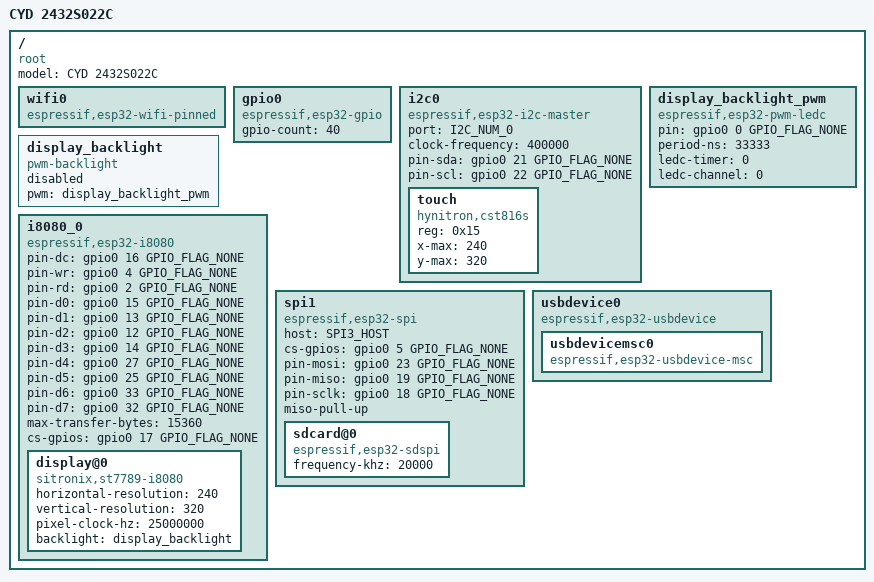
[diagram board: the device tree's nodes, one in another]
/dts-v1/;

#include <tactility/bindings/root.h>
#include <tactility/bindings/esp32_wifi_pinned.h>
#include <tactility/bindings/esp32_gpio.h>
#include <tactility/bindings/esp32_i2c_master.h>
#include <tactility/bindings/esp32_spi.h>
#include <tactility/bindings/esp32_sdspi.h>
#include <tactility/bindings/esp32_i8080.h>
#include <tactility/bindings/esp32_pwm_ledc.h>
#include <tactility/bindings/pwm_backlight.h>
#include <tactility/bindings/esp32_usbdevice.h>
#include <bindings/st7789_i8080.h>
#include <bindings/cst816s.h>

/ {
	compatible = "root";
	model = "CYD 2432S022C";

	wifi0 {
		compatible = "espressif,esp32-wifi-pinned";
	};

	gpio0 {
		compatible = "espressif,esp32-gpio";
		gpio-count = <40>;
	};

	i2c0 {
		compatible = "espressif,esp32-i2c-master";
		port = <I2C_NUM_0>;
		clock-frequency = <400000>;
		pin-sda = <&gpio0 21 GPIO_FLAG_NONE>;
		pin-scl = <&gpio0 22 GPIO_FLAG_NONE>;

		touch {
			compatible = "hynitron,cst816s";
			reg = <0x15>;
			x-max = <240>;
			y-max = <320>;
		};
	};

	display_backlight_pwm {
		compatible = "espressif,esp32-pwm-ledc";
		pin = <&gpio0 0 GPIO_FLAG_NONE>;
		period-ns = <33333>;
		ledc-timer = <0>;
		ledc-channel = <0>;
	};

	display_backlight {
		compatible = "pwm-backlight";
		// Off by default so display power-on won't show the screen from before the last power loss.
		// The display backlight is turned on during the boot process.
		status = "disabled";
		pwm = <&display_backlight_pwm>;
	};

	i8080_0 {
		compatible = "espressif,esp32-i8080";
		pin-dc = <&gpio0 16 GPIO_FLAG_NONE>;
		pin-wr = <&gpio0 4 GPIO_FLAG_NONE>;
		pin-rd = <&gpio0 2 GPIO_FLAG_NONE>;
		pin-d0 = <&gpio0 15 GPIO_FLAG_NONE>;
		pin-d1 = <&gpio0 13 GPIO_FLAG_NONE>;
		pin-d2 = <&gpio0 12 GPIO_FLAG_NONE>;
		pin-d3 = <&gpio0 14 GPIO_FLAG_NONE>;
		pin-d4 = <&gpio0 27 GPIO_FLAG_NONE>;
		pin-d5 = <&gpio0 25 GPIO_FLAG_NONE>;
		pin-d6 = <&gpio0 33 GPIO_FLAG_NONE>;
		pin-d7 = <&gpio0 32 GPIO_FLAG_NONE>;
		// 240 * (320 / 10 partial buffer) * 2 bytes/pixel = 15360 bytes
		max-transfer-bytes = <15360>;
		cs-gpios = <&gpio0 17 GPIO_FLAG_NONE>;

		display@0 {
			compatible = "sitronix,st7789-i8080";
			horizontal-resolution = <240>;
			vertical-resolution = <320>;
			pixel-clock-hz = <25000000>;
			backlight = <&display_backlight>;
		};
	};

	spi1 {
		compatible = "espressif,esp32-spi";
		host = <SPI3_HOST>;
		cs-gpios = <&gpio0 5 GPIO_FLAG_NONE>;
		pin-mosi = <&gpio0 23 GPIO_FLAG_NONE>;
		pin-miso = <&gpio0 19 GPIO_FLAG_NONE>;
		pin-sclk = <&gpio0 18 GPIO_FLAG_NONE>;
		miso-pull-up;

		sdcard@0 {
			compatible = "espressif,esp32-sdspi";
			frequency-khz = <20000>;
		};
	};

	usbdevice0 {
		compatible = "espressif,esp32-usbdevice";

		usbdevicemsc0 {
			compatible = "espressif,esp32-usbdevice-msc";
		};
	};
};
